AUTOSAR XML (schema 4-0-3)
package /AUTOSAR/Services/Csm
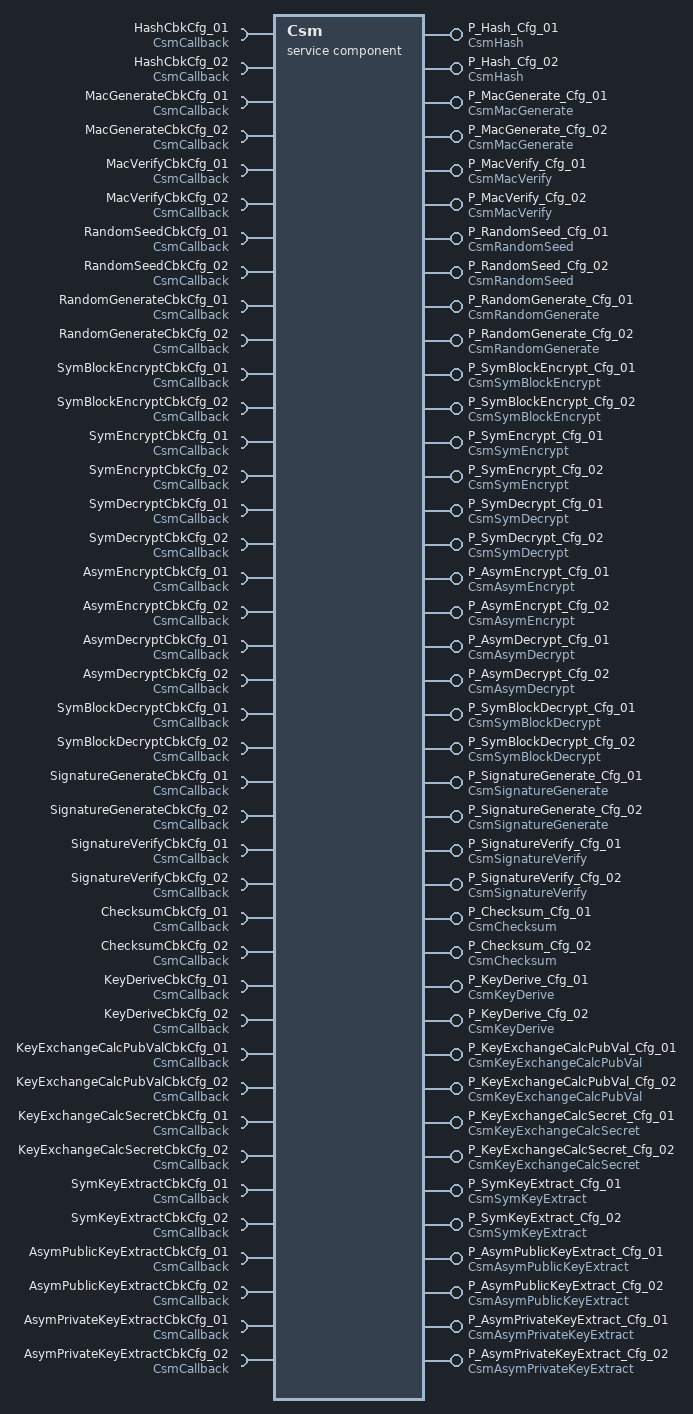
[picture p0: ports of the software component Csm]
  service sw component type Csm
    provide port P_Hash_Cfg_01: provided-interface=CsmHash
    require port HashCbkCfg_01: required-interface=CsmCallback
    provide port P_Hash_Cfg_02: provided-interface=CsmHash
    require port HashCbkCfg_02: required-interface=CsmCallback
    provide port P_MacGenerate_Cfg_01: provided-interface=CsmMacGenerate
    require port MacGenerateCbkCfg_01: required-interface=CsmCallback
    provide port P_MacGenerate_Cfg_02: provided-interface=CsmMacGenerate
    require port MacGenerateCbkCfg_02: required-interface=CsmCallback
    provide port P_MacVerify_Cfg_01: provided-interface=CsmMacVerify
    require port MacVerifyCbkCfg_01: required-interface=CsmCallback
    provide port P_MacVerify_Cfg_02: provided-interface=CsmMacVerify
    require port MacVerifyCbkCfg_02: required-interface=CsmCallback
    provide port P_RandomSeed_Cfg_01: provided-interface=CsmRandomSeed
    require port RandomSeedCbkCfg_01: required-interface=CsmCallback
    provide port P_RandomSeed_Cfg_02: provided-interface=CsmRandomSeed
    require port RandomSeedCbkCfg_02: required-interface=CsmCallback
    provide port P_RandomGenerate_Cfg_01: provided-interface=CsmRandomGenerate
    require port RandomGenerateCbkCfg_01: required-interface=CsmCallback
    provide port P_RandomGenerate_Cfg_02: provided-interface=CsmRandomGenerate
    require port RandomGenerateCbkCfg_02: required-interface=CsmCallback
    provide port P_SymBlockEncrypt_Cfg_01: provided-interface=CsmSymBlockEncrypt
    require port SymBlockEncryptCbkCfg_01: required-interface=CsmCallback
    provide port P_SymBlockEncrypt_Cfg_02: provided-interface=CsmSymBlockEncrypt
    require port SymBlockEncryptCbkCfg_02: required-interface=CsmCallback
    provide port P_SymEncrypt_Cfg_01: provided-interface=CsmSymEncrypt
    require port SymEncryptCbkCfg_01: required-interface=CsmCallback
    provide port P_SymEncrypt_Cfg_02: provided-interface=CsmSymEncrypt
    require port SymEncryptCbkCfg_02: required-interface=CsmCallback
    provide port P_SymDecrypt_Cfg_01: provided-interface=CsmSymDecrypt
    require port SymDecryptCbkCfg_01: required-interface=CsmCallback
    provide port P_SymDecrypt_Cfg_02: provided-interface=CsmSymDecrypt
    require port SymDecryptCbkCfg_02: required-interface=CsmCallback
    provide port P_AsymEncrypt_Cfg_01: provided-interface=CsmAsymEncrypt
    require port AsymEncryptCbkCfg_01: required-interface=CsmCallback
    provide port P_AsymEncrypt_Cfg_02: provided-interface=CsmAsymEncrypt
    require port AsymEncryptCbkCfg_02: required-interface=CsmCallback
    provide port P_AsymDecrypt_Cfg_01: provided-interface=CsmAsymDecrypt
    require port AsymDecryptCbkCfg_01: required-interface=CsmCallback
    provide port P_AsymDecrypt_Cfg_02: provided-interface=CsmAsymDecrypt
    require port AsymDecryptCbkCfg_02: required-interface=CsmCallback
    provide port P_SymBlockDecrypt_Cfg_01: provided-interface=CsmSymBlockDecrypt
    require port SymBlockDecryptCbkCfg_01: required-interface=CsmCallback
    provide port P_SymBlockDecrypt_Cfg_02: provided-interface=CsmSymBlockDecrypt
    require port SymBlockDecryptCbkCfg_02: required-interface=CsmCallback
    provide port P_SignatureGenerate_Cfg_01: provided-interface=CsmSignatureGenerate
    require port SignatureGenerateCbkCfg_01: required-interface=CsmCallback
    provide port P_SignatureGenerate_Cfg_02: provided-interface=CsmSignatureGenerate
    require port SignatureGenerateCbkCfg_02: required-interface=CsmCallback
    provide port P_SignatureVerify_Cfg_01: provided-interface=CsmSignatureVerify
    require port SignatureVerifyCbkCfg_01: required-interface=CsmCallback
    provide port P_SignatureVerify_Cfg_02: provided-interface=CsmSignatureVerify
    require port SignatureVerifyCbkCfg_02: required-interface=CsmCallback
    provide port P_Checksum_Cfg_01: provided-interface=CsmChecksum
    require port ChecksumCbkCfg_01: required-interface=CsmCallback
    provide port P_Checksum_Cfg_02: provided-interface=CsmChecksum
    require port ChecksumCbkCfg_02: required-interface=CsmCallback
    provide port P_KeyDerive_Cfg_01: provided-interface=CsmKeyDerive
    require port KeyDeriveCbkCfg_01: required-interface=CsmCallback
    provide port P_KeyDerive_Cfg_02: provided-interface=CsmKeyDerive
    require port KeyDeriveCbkCfg_02: required-interface=CsmCallback
    provide port P_KeyExchangeCalcPubVal_Cfg_01: provided-interface=CsmKeyExchangeCalcPubVal
    require port KeyExchangeCalcPubValCbkCfg_01: required-interface=CsmCallback
    provide port P_KeyExchangeCalcPubVal_Cfg_02: provided-interface=CsmKeyExchangeCalcPubVal
    require port KeyExchangeCalcPubValCbkCfg_02: required-interface=CsmCallback
    provide port P_KeyExchangeCalcSecret_Cfg_01: provided-interface=CsmKeyExchangeCalcSecret
    require port KeyExchangeCalcSecretCbkCfg_01: required-interface=CsmCallback
    provide port P_KeyExchangeCalcSecret_Cfg_02: provided-interface=CsmKeyExchangeCalcSecret
    require port KeyExchangeCalcSecretCbkCfg_02: required-interface=CsmCallback
    provide port P_SymKeyExtract_Cfg_01: provided-interface=CsmSymKeyExtract
    require port SymKeyExtractCbkCfg_01: required-interface=CsmCallback
    provide port P_SymKeyExtract_Cfg_02: provided-interface=CsmSymKeyExtract
    require port SymKeyExtractCbkCfg_02: required-interface=CsmCallback
    provide port P_AsymPublicKeyExtract_Cfg_01: provided-interface=CsmAsymPublicKeyExtract
    require port AsymPublicKeyExtractCbkCfg_01: required-interface=CsmCallback
    provide port P_AsymPublicKeyExtract_Cfg_02: provided-interface=CsmAsymPublicKeyExtract
    require port AsymPublicKeyExtractCbkCfg_02: required-interface=CsmCallback
    provide port P_AsymPrivateKeyExtract_Cfg_01: provided-interface=CsmAsymPrivateKeyExtract
    require port AsymPrivateKeyExtractCbkCfg_01: required-interface=CsmCallback
    provide port P_AsymPrivateKeyExtract_Cfg_02: provided-interface=CsmAsymPrivateKeyExtract
    require port AsymPrivateKeyExtractCbkCfg_02: required-interface=CsmCallback
    behavior IB_CSM: handle-termination-and-restart=NO-SUPPORT
      112 x operation invoked event:
        EV_HashStart1: start-on-event=RE_HashStart, operation=P_Hash_Cfg_01.HashStart
        EV_HashUpdate1: start-on-event=RE_HashUpdate, operation=P_Hash_Cfg_01.HashUpdate
        EV_HashFinish1: start-on-event=RE_HashFinish, operation=P_Hash_Cfg_01.HashFinish
        EV_HashStart2: start-on-event=RE_HashStart, operation=P_Hash_Cfg_02.HashStart
        EV_HashUpdate2: start-on-event=RE_HashUpdate, operation=P_Hash_Cfg_02.HashUpdate
        EV_HashFinish2: start-on-event=RE_HashFinish, operation=P_Hash_Cfg_02.HashFinish
        EV_MacGenerateStart1: start-on-event=RE_MacGenerateStart, operation=P_MacGenerate_Cfg_01.MacGenerateStart
        EV_MacGenerateUpdate1: start-on-event=RE_MacGenerateUpdate, operation=P_MacGenerate_Cfg_01.MacGenerateUpdate
        EV_MacGenerateFinish1: start-on-event=RE_MacGenerateFinish, operation=P_MacGenerate_Cfg_01.MacGenerateFinish
        EV_MacGenerateStart2: start-on-event=RE_MacGenerateStart, operation=P_MacGenerate_Cfg_02.MacGenerateStart
        EV_MacGenerateUpdate2: start-on-event=RE_MacGenerateUpdate, operation=P_MacGenerate_Cfg_02.MacGenerateUpdate
        EV_MacGenerateFinish2: start-on-event=RE_MacGenerateFinish, operation=P_MacGenerate_Cfg_02.MacGenerateFinish
        EV_MacVerifyStart1: start-on-event=RE_MacVerifyStart, operation=P_MacVerify_Cfg_01.MacVerifyStart
        EV_MacVerifyUpdate1: start-on-event=RE_MacVerifyUpdate, operation=P_MacVerify_Cfg_01.MacVerifyUpdate
        EV_MacVerifyFinish1: start-on-event=RE_MacVerifyFinish, operation=P_MacVerify_Cfg_01.MacVerifyFinish
        EV_MacVerifyStart2: start-on-event=RE_MacVerifyStart, operation=P_MacVerify_Cfg_02.MacVerifyStart
        EV_MacVerifyUpdate2: start-on-event=RE_MacVerifyUpdate, operation=P_MacVerify_Cfg_02.MacVerifyUpdate
        EV_MacVerifyFinish2: start-on-event=RE_MacVerifyFinish, operation=P_MacVerify_Cfg_02.MacVerifyFinish
        EV_RandomSeedStart1: start-on-event=RE_RandomSeedStart, operation=P_RandomSeed_Cfg_01.RandomSeedStart
        EV_RandomSeedUpdate1: start-on-event=RE_RandomSeedUpdate, operation=P_RandomSeed_Cfg_01.RandomSeedUpdate
        EV_RandomSeedFinish1: start-on-event=RE_RandomSeedFinish, operation=P_RandomSeed_Cfg_01.RandomSeedFinish
        EV_RandomSeedStart2: start-on-event=RE_RandomSeedStart, operation=P_RandomSeed_Cfg_02.RandomSeedStart
        EV_RandomSeedUpdate2: start-on-event=RE_RandomSeedUpdate, operation=P_RandomSeed_Cfg_02.RandomSeedUpdate
        EV_RandomSeedFinish2: start-on-event=RE_RandomSeedFinish, operation=P_RandomSeed_Cfg_02.RandomSeedFinish
        EV_RandomGenerate1: start-on-event=RE_RandomGenerate, operation=P_RandomGenerate_Cfg_01.RandomGenerate
        EV_RandomGenerate2: start-on-event=RE_RandomGenerate, operation=P_RandomGenerate_Cfg_01.RandomGenerate
        EV_SymBlockEncryptStart1: start-on-event=RE_SymBlockEncryptStart, operation=P_SymBlockEncrypt_Cfg_01.SymBlockEncryptStart
        EV_SymBlockEncryptUpdate1: start-on-event=RE_SymBlockEncryptUpdate, operation=P_SymBlockEncrypt_Cfg_01.SymBlockEncryptUpdate
        EV_SymBlockEncryptFinish1: start-on-event=RE_SymBlockEncryptFinish, operation=P_SymBlockEncrypt_Cfg_01.SymBlockEncryptFinish
        EV_SymBlockEncryptStart2: start-on-event=RE_SymBlockEncryptStart, operation=P_SymBlockEncrypt_Cfg_02.SymBlockEncryptStart
        EV_SymBlockEncryptUpdate2: start-on-event=RE_SymBlockEncryptUpdate, operation=P_SymBlockEncrypt_Cfg_02.SymBlockEncryptUpdate
        EV_SymBlockEncryptFinish2: start-on-event=RE_SymBlockEncryptFinish, operation=P_SymBlockEncrypt_Cfg_02.SymBlockEncryptFinish
        EV_SymEncryptStart1: start-on-event=RE_SymEncryptStart, operation=P_SymEncrypt_Cfg_01.SymEncryptStart
        EV_SymEncryptUpdate1: start-on-event=RE_SymEncryptUpdate, operation=P_SymEncrypt_Cfg_01.SymEncryptUpdate
        EV_SymEncryptFinish1: start-on-event=RE_SymEncryptFinish, operation=P_SymEncrypt_Cfg_01.SymEncryptFinish
        EV_SymEncryptStart2: start-on-event=RE_SymEncryptStart, operation=P_SymEncrypt_Cfg_02.SymEncryptStart
        EV_SymEncryptUpdate2: start-on-event=RE_SymEncryptUpdate, operation=P_SymEncrypt_Cfg_02.SymEncryptUpdate
        EV_SymEncryptFinish2: start-on-event=RE_SymEncryptFinish, operation=P_SymEncrypt_Cfg_02.SymEncryptFinish
        EV_SymDecryptStart1: start-on-event=RE_SymDecryptStart, operation=P_SymDecrypt_Cfg_01.SymDecryptStart
        EV_SymDecryptUpdate1: start-on-event=RE_SymDecryptUpdate, operation=P_SymDecrypt_Cfg_01.SymDecryptUpdate
        EV_SymDecryptFinish1: start-on-event=RE_SymDecryptFinish, operation=P_SymDecrypt_Cfg_01.SymDecryptFinish
        EV_SymDecryptStart2: start-on-event=RE_SymDecryptStart, operation=P_SymDecrypt_Cfg_02.SymDecryptStart
        EV_SymDecryptUpdate2: start-on-event=RE_SymDecryptUpdate, operation=P_SymDecrypt_Cfg_02.SymDecryptUpdate
        EV_SymDecryptFinish2: start-on-event=RE_SymDecryptFinish, operation=P_SymDecrypt_Cfg_02.SymDecryptFinish
        EV_AsymEncryptStart1: start-on-event=RE_AsymEncryptStart, operation=P_AsymEncrypt_Cfg_01.AsymEncryptStart
        EV_AsymEncryptUpdate1: start-on-event=RE_AsymEncryptUpdate, operation=P_AsymEncrypt_Cfg_01.AsymEncryptUpdate
        EV_AsymEncryptFinish1: start-on-event=RE_AsymEncryptFinish, operation=P_AsymEncrypt_Cfg_01.AsymEncryptFinish
        EV_AsymEncryptStart2: start-on-event=RE_AsymEncryptStart, operation=P_AsymEncrypt_Cfg_02.AsymEncryptStart
        EV_AsymEncryptUpdate2: start-on-event=RE_AsymEncryptUpdate, operation=P_AsymEncrypt_Cfg_02.AsymEncryptUpdate
        EV_AsymEncryptFinish2: start-on-event=RE_AsymEncryptFinish, operation=P_AsymEncrypt_Cfg_02.AsymEncryptFinish
        EV_AsymDecryptStart1: start-on-event=RE_AsymDecryptStart, operation=P_AsymDecrypt_Cfg_01.AsymDecryptStart
        EV_AsymDecryptUpdate1: start-on-event=RE_AsymDecryptUpdate, operation=P_AsymDecrypt_Cfg_01.AsymDecryptUpdate
        EV_AsymDecryptFinish1: start-on-event=RE_AsymDecryptFinish, operation=P_AsymDecrypt_Cfg_01.AsymDecryptFinish
        EV_AsymDecryptStart2: start-on-event=RE_AsymDecryptStart, operation=P_AsymDecrypt_Cfg_02.AsymDecryptStart
        EV_AsymDecryptUpdate2: start-on-event=RE_AsymDecryptUpdate, operation=P_AsymDecrypt_Cfg_02.AsymDecryptUpdate
        EV_AsymDecryptFinish2: start-on-event=RE_AsymDecryptFinish, operation=P_AsymDecrypt_Cfg_02.AsymDecryptFinish
        EV_SymBlockDecryptStart1: start-on-event=RE_SymBlockDecryptStart, operation=P_SymBlockDecrypt_Cfg_01.SymBlockDecryptStart
        EV_SymBlockDecryptUpdate1: start-on-event=RE_SymBlockDecryptUpdate, operation=P_SymBlockDecrypt_Cfg_01.SymBlockDecryptUpdate
        EV_SymBlockDecryptFinish1: start-on-event=RE_SymBlockDecryptFinish, operation=P_SymBlockDecrypt_Cfg_01.SymBlockDecryptFinish
        EV_SymBlockDecryptStart2: start-on-event=RE_SymBlockDecryptStart, operation=P_SymBlockDecrypt_Cfg_02.SymBlockDecryptStart
        EV_SymBlockDecryptUpdate2: start-on-event=RE_SymBlockDecryptUpdate, operation=P_SymBlockDecrypt_Cfg_02.SymBlockDecryptUpdate
        EV_SymBlockDecryptFinish2: start-on-event=RE_SymBlockDecryptFinish, operation=P_SymBlockDecrypt_Cfg_02.SymBlockDecryptFinish
        EV_SignatureGenerateStart1: start-on-event=RE_SignatureGenerateStart, operation=P_SignatureGenerate_Cfg_01.SignatureGenerateStart
        EV_SignatureGenerateUpdate1: start-on-event=RE_SignatureGenerateUpdate, operation=P_SignatureGenerate_Cfg_01.SignatureGenerateUpdate
        EV_SignatureGenerateFinish1: start-on-event=RE_SignatureGenerateFinish, operation=P_SignatureGenerate_Cfg_01.SignatureGenerateFinish
        EV_SignatureGenerateStart2: start-on-event=RE_SignatureGenerateStart, operation=P_SignatureGenerate_Cfg_02.SignatureGenerateStart
        EV_SignatureGenerateUpdate2: start-on-event=RE_SignatureGenerateUpdate, operation=P_SignatureGenerate_Cfg_02.SignatureGenerateUpdate
        EV_SignatureGenerateFinish2: start-on-event=RE_SignatureGenerateFinish, operation=P_SignatureGenerate_Cfg_02.SignatureGenerateFinish
        EV_SignatureVerifyStart1: start-on-event=RE_SignatureVerifyStart, operation=P_SignatureVerify_Cfg_01.SignatureVerifyStart
        EV_SignatureVerifyUpdate1: start-on-event=RE_SignatureVerifyUpdate, operation=P_SignatureVerify_Cfg_01.SignatureVerifyUpdate
        EV_SignatureVerifyFinish1: start-on-event=RE_SignatureVerifyFinish, operation=P_SignatureVerify_Cfg_01.SignatureVerifyFinish
        EV_SignatureVerifyStart2: start-on-event=RE_SignatureVerifyStart, operation=P_SignatureVerify_Cfg_02.SignatureVerifyStart
        EV_SignatureVerifyUpdate2: start-on-event=RE_SignatureVerifyUpdate, operation=P_SignatureVerify_Cfg_02.SignatureVerifyUpdate
        EV_SignatureVerifyFinish2: start-on-event=RE_SignatureVerifyFinish, operation=P_SignatureVerify_Cfg_02.SignatureVerifyFinish
        EV_ChecksumStart1: start-on-event=RE_ChecksumStart, operation=P_Checksum_Cfg_01.ChecksumStart
        EV_ChecksumUpdate1: start-on-event=RE_ChecksumUpdate, operation=P_Checksum_Cfg_01.ChecksumUpdate
        EV_ChecksumFinish1: start-on-event=RE_ChecksumFinish, operation=P_Checksum_Cfg_01.ChecksumFinish
        EV_ChecksumStart2: start-on-event=RE_ChecksumStart, operation=P_Checksum_Cfg_02.ChecksumStart
        EV_ChecksumUpdate2: start-on-event=RE_ChecksumUpdate, operation=P_Checksum_Cfg_02.ChecksumUpdate
        EV_ChecksumFinish2: start-on-event=RE_ChecksumFinish, operation=P_Checksum_Cfg_02.ChecksumFinish
        EV_KeyDeriveStart1: start-on-event=RE_KeyDeriveStart, operation=P_KeyDerive_Cfg_01.KeyDeriveStart
        EV_KeyDeriveUpdate1: start-on-event=RE_KeyDeriveUpdate, operation=P_KeyDerive_Cfg_01.KeyDeriveUpdate
        EV_KeyDeriveFinish1: start-on-event=RE_KeyDeriveFinish, operation=P_KeyDerive_Cfg_01.KeyDeriveFinish
        EV_KeyDeriveStart2: start-on-event=RE_KeyDeriveStart, operation=P_KeyDerive_Cfg_02.KeyDeriveStart
        EV_KeyDeriveUpdate2: start-on-event=RE_KeyDeriveUpdate, operation=P_KeyDerive_Cfg_02.KeyDeriveUpdate
        EV_KeyDeriveFinish2: start-on-event=RE_KeyDeriveFinish, operation=P_KeyDerive_Cfg_02.KeyDeriveFinish
        EV_KeyExchangeCalcPubVal1: start-on-event=RE_KeyExchangeCalcPubVal, operation=P_KeyExchangeCalcPubVal_Cfg_01.KeyExchangeCalcPubVal
        EV_KeyExchangeCalcPubVal2: start-on-event=RE_KeyExchangeCalcPubVal, operation=P_KeyExchangeCalcPubVal_Cfg_02.KeyExchangeCalcPubVal
        EV_KeyExchangeCalcSecretStart1: start-on-event=RE_KeyExchangeCalcSecretStart, operation=P_KeyExchangeCalcSecret_Cfg_01.KeyExchangeCalcSecretStart
        EV_KeyExchangeCalcSecretUpdate1: start-on-event=RE_KeyExchangeCalcSecretUpdate, operation=P_KeyExchangeCalcSecret_Cfg_01.KeyExchangeCalcSecretUpdate
        EV_KeyExchangeCalcSecretFinish1: start-on-event=RE_KeyExchangeCalcSecretFinish, operation=P_KeyExchangeCalcSecret_Cfg_01.KeyExchangeCalcSecretFinish
        EV_KeyExchangeCalcSecretStart2: start-on-event=RE_KeyExchangeCalcSecretStart, operation=P_KeyExchangeCalcSecret_Cfg_02.KeyExchangeCalcSecretStart
        EV_KeyExchangeCalcSecretUpdate2: start-on-event=RE_KeyExchangeCalcSecretUpdate, operation=P_KeyExchangeCalcSecret_Cfg_02.KeyExchangeCalcSecretUpdate
        EV_KeyExchangeCalcSecretFinish2: start-on-event=RE_KeyExchangeCalcSecretFinish, operation=P_KeyExchangeCalcSecret_Cfg_02.KeyExchangeCalcSecretFinish
        EV_SymKeyExtractStart1: start-on-event=RE_SymKeyExtractStart, operation=P_SymKeyExtract_Cfg_01.SymKeyExtractStart
        EV_SymKeyExtractUpdate1: start-on-event=RE_SymKeyExtractUpdate, operation=P_SymKeyExtract_Cfg_01.SymKeyExtractUpdate
        EV_SymKeyExtractFinish1: start-on-event=RE_SymKeyExtractFinish, operation=P_SymKeyExtract_Cfg_01.SymKeyExtractFinish
        EV_SymKeyExtractStart2: start-on-event=RE_SymKeyExtractStart, operation=P_SymKeyExtract_Cfg_02.SymKeyExtractStart
        EV_SymKeyExtractUpdate2: start-on-event=RE_SymKeyExtractUpdate, operation=P_SymKeyExtract_Cfg_02.SymKeyExtractUpdate
        EV_SymKeyExtractFinish2: start-on-event=RE_SymKeyExtractFinish, operation=P_SymKeyExtract_Cfg_02.SymKeyExtractFinish
        EV_AsymPublicKeyExtractStart1: start-on-event=RE_AsymPublicKeyExtractStart, operation=P_AsymPublicKeyExtract_Cfg_01.AsymPublicKeyExtractStart
        EV_AsymPublicKeyExtractUpdate1: start-on-event=RE_AsymPublicKeyExtractUpdate, operation=P_AsymPublicKeyExtract_Cfg_01.AsymPublicKeyExtractUpdate
        EV_AsymPublicKeyExtractFinish1: start-on-event=RE_AsymPublicKeyExtractFinish, operation=P_AsymPublicKeyExtract_Cfg_01.AsymPublicKeyExtractFinish
        EV_AsymPublicKeyExtractStart2: start-on-event=RE_AsymPublicKeyExtractStart, operation=P_AsymPublicKeyExtract_Cfg_02.AsymPublicKeyExtractStart
        EV_AsymPublicKeyExtractUpdate2: start-on-event=RE_AsymPublicKeyExtractUpdate, operation=P_AsymPublicKeyExtract_Cfg_02.AsymPublicKeyExtractUpdate
        EV_AsymPublicKeyExtractFinish2: start-on-event=RE_AsymPublicKeyExtractFinish, operation=P_AsymPublicKeyExtract_Cfg_02.AsymPublicKeyExtractFinish
        EV_AsymPrivateKeyExtractStart1: start-on-event=RE_AsymPrivateKeyExtractStart, operation=P_AsymPrivateKeyExtract_Cfg_01.AsymPrivateKeyExtractStart
        EV_AsymPrivateKeyExtractUpdate1: start-on-event=RE_AsymPrivateKeyExtractUpdate, operation=P_AsymPrivateKeyExtract_Cfg_01.AsymPrivateKeyExtractUpdate
        EV_AsymPrivateKeyExtractFinish1: start-on-event=RE_AsymPrivateKeyExtractFinish, operation=P_AsymPrivateKeyExtract_Cfg_01.AsymPrivateKeyExtractFinish
        EV_AsymPrivateKeyExtractStart2: start-on-event=RE_AsymPrivateKeyExtractStart, operation=P_AsymPrivateKeyExtract_Cfg_02.AsymPrivateKeyExtractStart
        EV_AsymPrivateKeyExtractUpdate2: start-on-event=RE_AsymPrivateKeyExtractUpdate, operation=P_AsymPrivateKeyExtract_Cfg_02.AsymPrivateKeyExtractUpdate
        EV_AsymPrivateKeyExtractFinish2: start-on-event=RE_AsymPrivateKeyExtractFinish, operation=P_AsymPrivateKeyExtract_Cfg_02.AsymPrivateKeyExtractFinish
      port-api-options:
        {indirect-api=true, port-defined-argument-value{value=0, value-type=uint16}, port=P_Hash_Cfg_01}
        {indirect-api=true, port-defined-argument-value{value=1, value-type=uint16}, port=P_Hash_Cfg_02}
        {indirect-api=true, port-defined-argument-value{value=0, value-type=uint16}, port=P_MacGenerate_Cfg_01}
        {indirect-api=true, port-defined-argument-value{value=1, value-type=uint16}, port=P_MacGenerate_Cfg_02}
        {indirect-api=true, port-defined-argument-value{value=0, value-type=uint16}, port=P_MacVerify_Cfg_01}
        {indirect-api=true, port-defined-argument-value{value=1, value-type=uint16}, port=P_MacVerify_Cfg_02}
        {indirect-api=true, port-defined-argument-value{value=0, value-type=uint16}, port=P_RandomSeed_Cfg_01}
        {indirect-api=true, port-defined-argument-value{value=1, value-type=uint16}, port=P_RandomSeed_Cfg_02}
        {indirect-api=true, port-defined-argument-value{value=0, value-type=uint16}, port=P_RandomGenerate_Cfg_01}
        {indirect-api=true, port-defined-argument-value{value=1, value-type=uint16}, port=P_RandomGenerate_Cfg_02}
        {indirect-api=true, port-defined-argument-value{value=0, value-type=uint16}, port=P_SymBlockEncrypt_Cfg_01}
        {indirect-api=true, port-defined-argument-value{value=1, value-type=uint16}, port=P_SymBlockEncrypt_Cfg_02}
        {indirect-api=true, port-defined-argument-value{value=0, value-type=uint16}, port=P_SymEncrypt_Cfg_01}
        {indirect-api=true, port-defined-argument-value{value=1, value-type=uint16}, port=P_SymEncrypt_Cfg_02}
        {indirect-api=true, port-defined-argument-value{value=0, value-type=uint16}, port=P_SymDecrypt_Cfg_01}
        {indirect-api=true, port-defined-argument-value{value=1, value-type=uint16}, port=P_SymDecrypt_Cfg_02}
        {indirect-api=true, port-defined-argument-value{value=0, value-type=uint16}, port=P_AsymEncrypt_Cfg_01}
        {indirect-api=true, port-defined-argument-value{value=1, value-type=uint16}, port=P_AsymEncrypt_Cfg_02}
        {indirect-api=true, port-defined-argument-value{value=0, value-type=uint16}, port=P_AsymDecrypt_Cfg_01}
        {indirect-api=true, port-defined-argument-value{value=1, value-type=uint16}, port=P_AsymDecrypt_Cfg_02}
        {indirect-api=true, port-defined-argument-value{value=0, value-type=uint16}, port=P_SymBlockDecrypt_Cfg_01}
        {indirect-api=true, port-defined-argument-value{value=1, value-type=uint16}, port=P_SymBlockDecrypt_Cfg_02}
        {indirect-api=true, port-defined-argument-value{value=0, value-type=uint16}, port=P_SignatureGenerate_Cfg_01}
        {indirect-api=true, port-defined-argument-value{value=1, value-type=uint16}, port=P_SignatureGenerate_Cfg_02}
        {indirect-api=true, port-defined-argument-value{value=0, value-type=uint16}, port=P_SignatureVerify_Cfg_01}
        {indirect-api=true, port-defined-argument-value{value=1, value-type=uint16}, port=P_SignatureVerify_Cfg_02}
        {indirect-api=true, port-defined-argument-value{value=0, value-type=uint16}, port=P_Checksum_Cfg_01}
        {indirect-api=true, port-defined-argument-value{value=1, value-type=uint16}, port=P_Checksum_Cfg_02}
        {indirect-api=true, port-defined-argument-value{value=0, value-type=uint16}, port=P_KeyDerive_Cfg_01}
        {indirect-api=true, port-defined-argument-value{value=1, value-type=uint16}, port=P_KeyDerive_Cfg_02}
        {indirect-api=true, port-defined-argument-value{value=0, value-type=uint16}, port=P_KeyExchangeCalcPubVal_Cfg_01}
        {indirect-api=true, port-defined-argument-value{value=1, value-type=uint16}, port=P_KeyExchangeCalcPubVal_Cfg_02}
        {indirect-api=true, port-defined-argument-value{value=0, value-type=uint16}, port=P_KeyExchangeCalcSecret_Cfg_01}
        {indirect-api=true, port-defined-argument-value{value=1, value-type=uint16}, port=P_KeyExchangeCalcSecret_Cfg_02}
        {indirect-api=true, port-defined-argument-value{value=0, value-type=uint16}, port=P_SymKeyExtract_Cfg_01}
        {indirect-api=true, port-defined-argument-value{value=1, value-type=uint16}, port=P_SymKeyExtract_Cfg_02}
        {indirect-api=true, port-defined-argument-value{value=0, value-type=uint16}, port=P_AsymPublicKeyExtract_Cfg_01}
        {indirect-api=true, port-defined-argument-value{value=1, value-type=uint16}, port=P_AsymPublicKeyExtract_Cfg_02}
        {indirect-api=true, port-defined-argument-value{value=0, value-type=uint16}, port=P_AsymPrivateKeyExtract_Cfg_01}
        {indirect-api=true, port-defined-argument-value{value=1, value-type=uint16}, port=P_AsymPrivateKeyExtract_Cfg_02}
      57 x runnable:
        RE_SymEncryptStart: symbol=Csm_RteSymEncryptStart
        RE_SymEncryptUpdate: symbol=Csm_RteSymEncryptUpdate
        RE_SymDecryptStart: symbol=Csm_RteSymDecryptStart
        RE_SymDecryptUpdate: symbol=Csm_RteSymDecryptUpdate
        RE_SymBlockEncryptStart: symbol=Csm_RteSymBlockEncryptStart
        RE_SymBlockEncryptUpdate: symbol=Csm_RteSymBlockEncryptUpdate
        RE_RandomSeedStart: symbol=Csm_RteRandomSeedStart
        RE_RandomSeedUpdate: symbol=Csm_RteRandomSeedUpdate
        RE_MacVerifyStart: symbol=Csm_RteMacVerifyStart
        RE_MacVerifyUpdate: symbol=Csm_RteMacVerifyUpdate
        RE_MacGenerateStart: symbol=Csm_RteMacGenerateStart
        RE_MacGenerateUpdate: symbol=Csm_RteMacGenerateUpdate
        RE_HashStart: symbol=Csm_RteHashStart
        RE_HashUpdate: symbol=Csm_RteHashUpdate
        RE_AsymEncryptStart: symbol=Csm_RteAsymEncryptStart
        RE_AsymEncryptUpdate: symbol=Csm_RteAsymEncryptUpdate
        RE_AsymDecryptStart: symbol=Csm_RteAsymDecryptStart
        RE_AsymDecryptUpdate: symbol=Csm_RteAsymDecryptUpdate
        RE_SymKeyExtractStart: symbol=Csm_RteSymKeyExtractStart
        RE_SymKeyExtractUpdate: symbol=Csm_RteSymKeyExtractUpdate
        RE_AsymPublicKeyExtractStart: symbol=Csm_RteAsymPublicKeyExtractStart
        RE_AsymPublicKeyExtractUpdate: symbol=Csm_RteAsymPublicKeyExtractUpdate
        RE_AsymPrivateKeyExtractStart: symbol=Csm_RteAsymPrivateKeyExtractStart
        RE_AsymPrivateKeyExtractUpdate: symbol=Csm_RteAsymPrivateKeyExtractUpdate
        RE_ChecksumStart: symbol=Csm_RteChecksumStart
        RE_ChecksumUpdate: symbol=Csm_RteChecksumUpdate
        RE_KeyDeriveStart: symbol=Csm_RteKeyDeriveStart
        RE_KeyDeriveUpdate: symbol=Csm_RteKeyDeriveUpdate
        RE_SymBlockDecryptStart: symbol=Csm_RteSymBlockDecryptStart
        RE_SymBlockDecryptUpdate: symbol=Csm_RteSymBlockDecryptUpdate
        RE_SignatureGenerateStart: symbol=Csm_RteSignatureGenerateStart
        RE_SignatureGenerateUpdate: symbol=Csm_RteSignatureGenerateUpdate
        RE_KeyExchangeCalcSecretStart: symbol=Csm_RteKeyExchangeCalcSecretStart
        RE_KeyExchangeCalcSecretUpdate: symbol=Csm_RteKeyExchangeCalcSecretUpdate
        RE_SignatureVerifyStart: symbol=Csm_RteSignatureVerifyStart
        RE_SignatureVerifyUpdate: symbol=Csm_RteSignatureVerifyUpdate
        Csm_MainFunction
        RE_HashFinish: symbol=Csm_RteHashFinish
          sync call SSP_HashCbkCfg_01: operation=HashCbkCfg_01.JobFinished, timeout=0.0
          sync call SSP_HashCbkCfg_02: operation=HashCbkCfg_02.JobFinished, timeout=0.0
        RE_MacGenerateFinish: symbol=Csm_RteMacGenerateFinish
          sync call SSP_MacGenerateCbkCfg_01: operation=MacGenerateCbkCfg_01.JobFinished, timeout=0.0
          sync call SSP_MacGenerateCbkCfg_02: operation=MacGenerateCbkCfg_02.JobFinished, timeout=0.0
        RE_MacVerifyFinish: symbol=Csm_RteMacVerifyFinish
          sync call SSP_MacVerifyCbkCfg_01: operation=MacVerifyCbkCfg_01.JobFinished, timeout=0.0
          sync call SSP_MacVerifyCbkCfg_02: operation=MacVerifyCbkCfg_02.JobFinished, timeout=0.0
        RE_RandomSeedFinish: symbol=Csm_RteRandomSeedFinish
          sync call SSP_RandomSeedCbkCfg_01: operation=RandomSeedCbkCfg_01.JobFinished, timeout=0.0
          sync call SSP_RandomSeedCbkCfg_02: operation=RandomSeedCbkCfg_02.JobFinished, timeout=0.0
        RE_SymBlockEncryptFinish: symbol=Csm_RteSymBlockEncryptFinish
          sync call SSP_SymBlockEncryptCbkCfg_01: operation=SymBlockEncryptCbkCfg_01.JobFinished, timeout=0.0
          sync call SSP_SymBlockEncryptCbkCfg_02: operation=SymBlockEncryptCbkCfg_02.JobFinished, timeout=0.0
        RE_SymEncryptFinish: symbol=Csm_RteSymEncryptFinish
          sync call SSP_SymEncryptCbkCfg_01: operation=SymEncryptCbkCfg_01.JobFinished, timeout=0.0
          sync call SSP_SymEncryptCbkCfg_02: operation=SymEncryptCbkCfg_02.JobFinished, timeout=0.0
        RE_SymDecryptFinish: symbol=Csm_RteSymDecryptFinish
          sync call SSP_SymDecryptCbkCfg_01: operation=SymDecryptCbkCfg_01.JobFinished, timeout=0.0
          sync call SSP_SymDecryptCbkCfg_02: operation=SymDecryptCbkCfg_02.JobFinished, timeout=0.0
        RE_RandomGenerate: symbol=Csm_RteRandomGenerateFinish
          sync call SSP_RandomGenerateCbkCfg_01: operation=RandomGenerateCbkCfg_01.JobFinished, timeout=0.0
          sync call SSP_RandomGenerateCbkCfg_02: operation=RandomGenerateCbkCfg_02.JobFinished, timeout=0.0
        RE_SymBlockDecryptFinish: symbol=Csm_RteSymBlockDecryptFinish
          sync call SSP_SymBlockDecryptCbkCfg_01: operation=SymBlockDecryptCbkCfg_01.JobFinished, timeout=0.0
          sync call SSP_SymBlockDecryptCbkCfg_02: operation=SymBlockDecryptCbkCfg_02.JobFinished, timeout=0.0
        RE_AsymEncryptFinish: symbol=Csm_RteAsymEncryptFinish
          sync call SSP_AsymEncryptCbkCfg_01: operation=AsymEncryptCbkCfg_01.JobFinished, timeout=0.0
          sync call SSP_AsymEncryptCbkCfg_02: operation=AsymEncryptCbkCfg_02.JobFinished, timeout=0.0
        RE_AsymDecryptFinish: symbol=Csm_RteAsymDecryptFinish
          sync call SSP_AsymDecryptCbkCfg_01: operation=AsymDecryptCbkCfg_01.JobFinished, timeout=0.0
          sync call SSP_AsymDecryptCbkCfg_02: operation=AsymDecryptCbkCfg_02.JobFinished, timeout=0.0
        RE_ChecksumFinish: symbol=Csm_RteChecksumFinish
          sync call SSP_ChecksumCbkCfg_01: operation=ChecksumCbkCfg_01.JobFinished, timeout=0.0
          sync call SSP_ChecksumCbkCfg_02: operation=ChecksumCbkCfg_02.JobFinished, timeout=0.0
        RE_KeyDeriveFinish: symbol=Csm_RteKeyDeriveFinish
          sync call SSP_KeyDeriveCbkCfg_01: operation=KeyDeriveCbkCfg_01.JobFinished, timeout=0.0
          sync call SSP_KeyDeriveCbkCfg_02: operation=KeyDeriveCbkCfg_02.JobFinished, timeout=0.0
        RE_KeyExchangeCalcPubVal: symbol=Csm_RteKeyExchangeCalcPubValFinish
          sync call SSP_KeyExchangeCalcPubValCbkCfg_01: operation=KeyExchangeCalcPubValCbkCfg_01.JobFinished, timeout=0.0
          sync call SSP_KeyExchangeCalcPubValCbkCfg_02: operation=KeyExchangeCalcPubValCbkCfg_02.JobFinished, timeout=0.0
        RE_KeyExchangeCalcSecretFinish: symbol=Csm_RteKeyExchangeCalcSecretFinish
          sync call SSP_KeyExchangeCalcSecretCbkCfg_01: operation=KeyExchangeCalcSecretCbkCfg_01.JobFinished, timeout=0.0
          sync call SSP_KeyExchangeCalcSecretCbkCfg_02: operation=KeyExchangeCalcSecretCbkCfg_02.JobFinished, timeout=0.0
        RE_SymKeyExtractFinish: symbol=Csm_RteSymKeyExtractFinish
          sync call SSP_SymKeyExtractCbkCfg_01: operation=SymKeyExtractCbkCfg_01.JobFinished, timeout=0.0
          sync call SSP_SymKeyExtractCbkCfg_02: operation=SymKeyExtractCbkCfg_02.JobFinished, timeout=0.0
        RE_AsymPublicKeyExtractFinish: symbol=Csm_RteAsymPublicKeyExtractFinish
          sync call SSP_AsymPublicKeyExtractCbkCfg_01: operation=AsymPublicKeyExtractCbkCfg_01.JobFinished, timeout=0.0
          sync call SSP_AsymPublicKeyExtractCbkCfg_02: operation=AsymPublicKeyExtractCbkCfg_02.JobFinished, timeout=0.0
        RE_AsymPrivateKeyExtractFinish: symbol=Csm_RteAsymPrivateKeyExtractFinish
          sync call SSP_AsymPrivateKeyExtractCbkCfg_01: operation=AsymPrivateKeyExtractCbkCfg_01.JobFinished, timeout=0.0
          sync call SSP_AsymPrivateKeyExtractCbkCfg_02: operation=AsymPrivateKeyExtractCbkCfg_02.JobFinished, timeout=0.0
        RE_SignatureGenerateFinish: symbol=Csm_RteSignatureGenerateFinish
          sync call SSP_SignatureGenerateCbkCfg_01: operation=SignatureGenerateCbkCfg_01.JobFinished, timeout=0.0
          sync call SSP_SignatureGenerateCbkCfg_02: operation=SignatureGenerateCbkCfg_02.JobFinished, timeout=0.0
        RE_SignatureVerifyFinish: symbol=Csm_RteSignatureVerifyFinish
          sync call SSP_SignatureVerifyCbkCfg_01: operation=SignatureVerifyCbkCfg_01.JobFinished, timeout=0.0
          sync call SSP_SignatureVerifyCbkCfg_02: operation=SignatureVerifyCbkCfg_02.JobFinished, timeout=0.0
  swc implementation IMPL_Csm: programming-language=C, sw-version=2.1.0, vendor-id=41, behavior=IB_CSM
